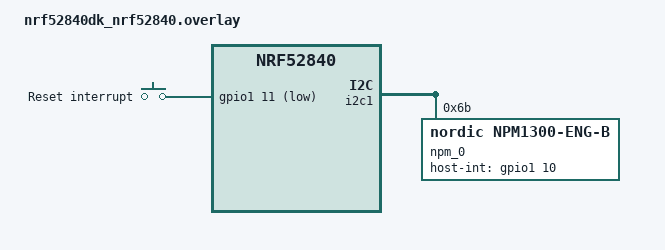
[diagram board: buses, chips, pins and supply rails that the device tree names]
/*
 * Copyright (c) 2023 Nordic Semiconductor ASA
 *
 * SPDX-License-Identifier: LicenseRef-Nordic-5-Clause
 */

&i2c1 {
	compatible = "nordic,nrf-twim";
	status = "okay";

	npm_0: npm1300@6b {
		status = "okay";
		compatible = "nordic,npm1300-eng-b";
		reg = <0x6b>;
		host-int-gpios = <&gpio1 10 (GPIO_PULL_DOWN | GPIO_ACTIVE_HIGH)>;
		pmic-int-pin = <0>;
		pmic-reset-pin = <1>;
	};
};

&i2c1_default {
	group1 {
		psels = <NRF_PSEL(TWIM_SDA, 0, 26)>, <NRF_PSEL(TWIM_SCL, 0, 27)>;
		bias-pull-up;
	};
};

/ {
	buttons {
		compatible = "gpio-keys";
		irq_res0: irq_res_0 {
			gpios = <&gpio1 11 (GPIO_PULL_UP | GPIO_ACTIVE_LOW)>;
			label = "Reset interrupt";
		};
	};

	aliases {
		irqres0 = &irq_res0;
	};
};
